# V850 register map
Vendor: Renesas; Series: E1/E2/CA2; File version: 1.2
NEC/Renesas V850 automotive grade ICs
CPU: V850 r1, little endian, no MPU, no FPU, 3 interrupt priority bits
Registers are 8-bit, read-write, reset 0x0 unless marked. A register's access mark holds for its fields unless they carry their own. Offsets are from the block's base; lines under a group give offsets from that group; [hi:lo] are bit positions; {n}, {i} and the like mark numbered series; 'fields as' and 'values as' point back to an identical list; <NAME> marks a mode.

## Memory map
0x00000000 Interrupt/Exception_Processing size 0x100 — The V850E/CA2 is provided with a dedicated interrupt controller (INTC) for interrupt servicing and can process a total of 64 maskable and three non-maskable interrupt requests. An interrupt is an event that occurs independently of program execution, and an exception is an event whose occurrence is dependent on program execution. Generally, an exception takes precedence over an interrupt. The V850E/CA2 can process interrupt requests from the on-chip peripheral hardware and external sources. Moreover, exception processing can be started by the TRAP instruction (software exception) or by generation of an exception event (i.e. fetching of an illegal opcode) (exception trap). Eight levels of software-programmable priorities can be specified for each interrupt request. Interrupt servicing starts after no fewer than 11 system clocks (343 ns (@ 32 MHz)) following the generation of an interrupt request.
0xFFFF3000 Programmable_Peripheral_I/O_(16KB_area) size 0x4000
0xFFFFF1FC Specific_Registers
0xFFFFF49A MEMORY — SRAM, External ROM, External I/O Interface
0xFFFFF540 TIMERD size 0x100
0xFFFFF600 TIMERC size 0x100 — 16 bit Timer / Counter
0xFFFFF648 TIMERG size 0x100

## Interrupts
0 INTCCC00 (TIMERC) — Timer C, generated by TIC00 capture register
4 TIMERD — Timer D interrupt
6 INTTMGn0 (TIMERG) — Timer Gn0 interrupt

## Specific_Registers
Base 0xFFFFF1FC
0xFFFFF06E VSWC reset 0x77 — Internal peripheral function wait control register (VSWC)
0xFFFFF1FC PRCMD — This command register (PRCMD) is to protect the registers that may have a significant influence on the application system (PSC, PSM) from an inadvertent write access, so that the system does not stop in case of a program hang-up.
  [7:0] REG7-REG0
0xFFFFF800 PRCMD — This command register (PHCMD) is to protect the registers that may have a significant influence on the application system (CKC, WCC, PCC) from an inadvertent write access, so that the system does not stop in case of a program hang-up.
  [7:0] REG7-REG0
0xFFFFF802 PHS — The flag PRERR in the peripheral status register PHS indicates protection error occurrence. This register can be read/written in 8-bit units or bit-wise.
  [0] PRERR

## Programmable_Peripheral_I/O_(16KB_area)
Base 0xFFFF3000
0xFFFFF064 BPC — Peripheral area selection control register (BPC)
  [15] PA15 — Enables/disables usage of programmable peripheral I/O area
    0=Disables usage of programmable peripheral I/O area; 1=Enables usage of programmable peripheral I/O area
  [13:0] PA0-PA13 — Specifies the bit 27 to bit 14 of the starting address of the programmable peripheral I/O area (The other bits are fixed at zero).
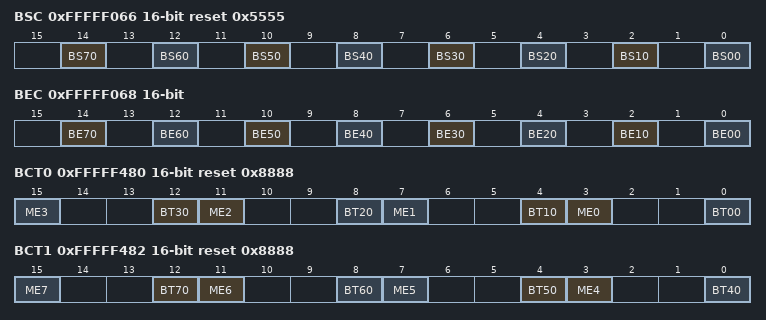
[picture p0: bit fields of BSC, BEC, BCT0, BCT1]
0xFFFFF066 BSC 16-bit reset 0x5555 — Bus size configuration register (BSC)
  [all] fields
    0=8 bit bus (Sets the data bus width of CSn area.); 1=16 bit bus (Sets the data bus width of CSn area.)
  [14] BS70 — Data Bus Width
  [12] BS60 — Data Bus Width
  [10] BS50 — Data Bus Width
  [8] BS40 — Data Bus Width
  [6] BS30 — Data Bus Width
  [4] BS20 — Data Bus Width
  [2] BS10 — Data Bus Width
  [0] BS00 — Data Bus Width
0xFFFFF068 BEC 16-bit — Endian configuration register (BEC)
  [all] fields
    0=Little Endian method; 1=Big Endian method
  [14] BE70 — Specifies the endianness of CS7.
  [12] BE60 — Specifies the endianness of CS6.
  [10] BE50 — Specifies the endianness of CS5.
  [8] BE40 — Specifies the endianness of CS4.
  [6] BE30 — Specifies the endianness of CS3.
  [4] BE20 — Specifies the endianness of CS2.
  [2] BE10 — Specifies the endianness of CS1.
  [0] BE00 — Specifies the endianness of CS0.
0xFFFFF480 BCT0 16-bit reset 0x8888 — Bus cycle configuration registers 0 (BCT0)
  [4n+3] ME{n} (n=0..3) — Memory Controller Enable {n}
    0=disable (Sets memory controller operation enable for each chip select signal CS{n}); 1=enable (Sets memory controller operation enable for each chip select signal CS{n})
  [12] BT30 — Bus Cycle Type 30
    0=SRAM, external I/O (Specifies the device to be connected to the CS3 signal.); 1=Page ROM (Specifies the device to be connected to the CS3 signal.)
  [8] BT20 — Bus Cycle Type 20
    0=SRAM, external I/O (Specifies the device to be connected to the CS2 signal.); 1=Page ROM (Specifies the device to be connected to the CS2 signal.)
  [4] BT10 — Bus Cycle Type 10
    0=SRAM, external I/O (Specifies the device to be connected to the CS1 signal.); 1=Page ROM (Specifies the device to be connected to the CS1 signal.)
  [0] BT00 — Bus Cycle Type 00
    0=SRAM, external I/O (Specifies the device to be connected to the CS0 signal.); 1=Page ROM (Specifies the device to be connected to the CS0 signal.)
0xFFFFF482 BCT1 16-bit reset 0x8888 — Bus cycle configuration registers 1 (BCT1)
  [4n-13] ME{n} (n=4..7) — Memory Controller Enable {n}
    values as BCT0.ME0
  [12] BT70 — Bus Cycle Type 70
    0=SRAM, external I/O (Specifies the device to be connected to the CS7 signal.); 1=Page ROM (Specifies the device to be connected to the CS7 signal.)
  [8] BT60 — Bus Cycle Type 60
    0=SRAM, external I/O (Specifies the device to be connected to the CS6 signal.); 1=Page ROM (Specifies the device to be connected to the CS6 signal.)
  [4] BT50 — Bus Cycle Type 50
    0=SRAM, external I/O (Specifies the device to be connected to the CS5 signal.); 1=Page ROM (Specifies the device to be connected to the CS5 signal.)
  [0] BT40 — Bus Cycle Type 40
    0=SRAM, external I/O (Specifies the device to be connected to the CS4 signal.); 1=Page ROM (Specifies the device to be connected to the CS4 signal.)

## Licence text in the file
GPLv3
